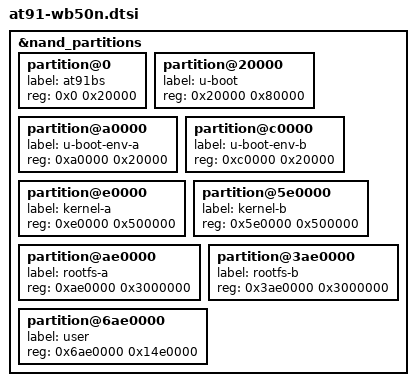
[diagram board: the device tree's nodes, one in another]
// SPDX-License-Identifier: GPL-2.0
/*
 * at91-wb50n.dtsi - Device Tree include file for WB50N Legacy CPU module
 *
 *  Copyright (C) 2018-2020 Ezurio
 *
 */

#include "at91-wb50n_common.dtsi"

&nand_partitions {
	partition@0 {
		label = "at91bs";
		reg = <0x0 0x20000>;
	};

	partition@20000 {
		label = "u-boot";
		reg = <0x20000 0x80000>;
	};

	partition@a0000 {
		label = "u-boot-env-a";
		reg = <0xa0000 0x20000>;
	};

	partition@c0000 {
		label = "u-boot-env-b";
		reg = <0xc0000 0x20000>;
	};

	partition@e0000 {
		label = "kernel-a";
		reg = <0xe0000 0x500000>;
	};

	partition@5e0000 {
		label = "kernel-b";
		reg = <0x5e0000 0x500000>;
	};

	partition@ae0000 {
		label = "rootfs-a";
		reg = <0xae0000 0x3000000>;
	};

	partition@3ae0000 {
		label = "rootfs-b";
		reg = <0x3ae0000 0x3000000>;
	};

	partition@6ae0000 {
		label = "user";
		reg = <0x6ae0000 0x14e0000>;
	};
};
